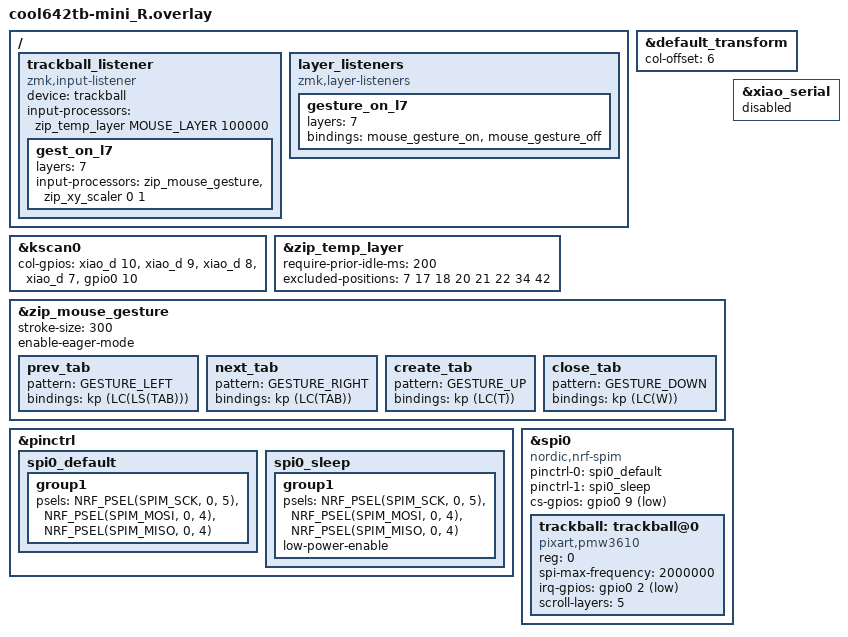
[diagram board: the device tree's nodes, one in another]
#include "cool642tb-mini.dtsi"
#include <input/processors.dtsi>
#include <zephyr/dt-bindings/input/input-event-codes.h>
#include <mouse-gesture.dtsi>   /* kot149 モジュール */

#define MOUSE_LAYER 4

&default_transform {
    col-offset = <6>;
};

&kscan0 {
        col-gpios
            = <&xiao_d 10 GPIO_ACTIVE_HIGH>
            , <&xiao_d 9 GPIO_ACTIVE_HIGH> 
            , <&xiao_d 8 GPIO_ACTIVE_HIGH> 
            , <&xiao_d 7 GPIO_ACTIVE_HIGH> 
            , <&gpio0 10 GPIO_ACTIVE_HIGH>
            ;
};

&zip_temp_layer {
    require-prior-idle-ms = <200>;
    excluded-positions = <
        7  // I(MB3)
        17 // H(MB4)
        18 // J(MB1)
        20 // L(MB2)
        21 // -(MB5)
        22 // LEFT_SHIFT
        34 // LEFT_CONTROL
        42 // RIGHT_CONTROL
    >;
};

&zip_mouse_gesture {
    stroke-size = <300>;
    enable-eager-mode;
    prev_tab { pattern = <GESTURE_LEFT>; bindings = <&kp (LC(LS(TAB)))>; };
    next_tab { pattern = <GESTURE_RIGHT>; bindings = <&kp (LC(TAB))>; };
    create_tab { pattern = <GESTURE_UP>; bindings = <&kp (LC(T))>; };
    close_tab { pattern = <GESTURE_DOWN>; bindings = <&kp (LC(W))>; };
};

/ {
    trackball_listener: trackball_listener {
        compatible = "zmk,input-listener";
        device = <&trackball>;

        input-processors = <&zip_temp_layer MOUSE_LAYER 100000>;

        gest_on_l7 {
            layers = <7>;
            input-processors = <&zip_mouse_gesture &zip_xy_scaler 0 1>;
        };

        //gest_on_l8 {
        //    layers = <8>;
        //    input-processors = <&zip_mouse_gesture_l8 &zip_xy_scaler 0 1>;
        //};

        //gest_on_l9 {
        //    layers = <9>;
        //    input-processors = <&zip_mouse_gesture_l9 &zip_xy_scaler 0 1>;
        //};
    };

    layer_listeners {
        compatible = "zmk,layer-listeners";

        // Layer 7 に入ったらジェスチャーON、抜けたらOFF
        gesture_on_l7 {
            layers = <7>;
            bindings = <&mouse_gesture_on &mouse_gesture_off>;
        };

        //gesture_on_l8 {
        //    layers = <8>;
        //    bindings = <&mouse_gesture_on &mouse_gesture_off>;
        //};

        //gesture_on_l9 {
        //    layers = <9>;
        //    bindings = <&mouse_gesture_on &mouse_gesture_off>;
        //};
    };
};

&pinctrl {
    spi0_default: spi0_default {
        group1 {
            psels = <NRF_PSEL(SPIM_SCK, 0, 5)>,
                <NRF_PSEL(SPIM_MOSI, 0, 4)>,
                <NRF_PSEL(SPIM_MISO, 0, 4)>;
        };
    };

    spi0_sleep: spi0_sleep {
        group1 {
            psels = <NRF_PSEL(SPIM_SCK, 0, 5)>,
                <NRF_PSEL(SPIM_MOSI, 0, 4)>,
                <NRF_PSEL(SPIM_MISO, 0, 4)>;
            low-power-enable;
        };
    };
};

&xiao_serial { status = "disabled"; };

&spi0 {
    status = "okay";
    compatible = "nordic,nrf-spim";
    pinctrl-0 = <&spi0_default>;
    pinctrl-1 = <&spi0_sleep>;
    pinctrl-names = "default", "sleep";
    cs-gpios = <&gpio0 9 GPIO_ACTIVE_LOW>;

    trackball: trackball@0 {
        status = "okay";
        compatible = "pixart,pmw3610";
        reg = <0>;
        spi-max-frequency = <2000000>;
        irq-gpios = <&gpio0 2 (GPIO_ACTIVE_LOW | GPIO_PULL_UP)>;
        //automouse-layer = <4>;
        scroll-layers = <5>;
    };
};
